# ESP32-C61 register map
Vendor: ESPRESSIF SYSTEMS (SHANGHAI) CO., LTD.; Series: ESP32 C-Series; File version: 1
CPU: RV32IMAC r0p0, little endian, no MPU, no FPU, 0 interrupt priority bits
Address unit: 32 bits
Registers are 32-bit, read-write, reset 0x0 unless marked. A register's access mark holds for its fields unless they carry their own. Offsets are from the block's base; [hi:lo] are bit positions; 'fields as' and 'values as' point back to an identical list.

## IO_MUX — Input/Output Multiplexer
Base 0x60090000
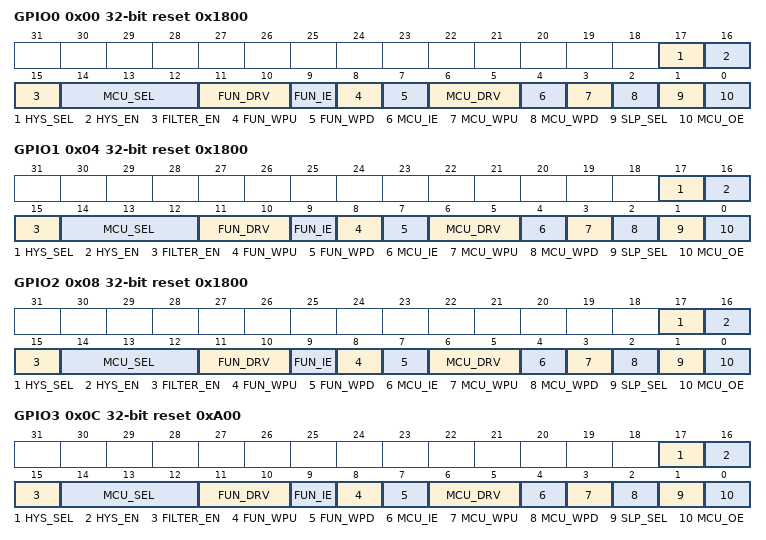
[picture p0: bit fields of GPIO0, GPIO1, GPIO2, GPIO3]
0x00 GPIO0 reset 0x1800 — IO_MUX Configure Register for pad XTAL_32K_P
  [17] HYS_SEL — Select enabling signals of the pad from software and efuse hardware. 1: Select enabling siganl from slftware. 0: Select enabling signal from efuse hardware.
  [16] HYS_EN — Software enables hysteresis function for the pad. 1: Hysteresis enabled. 0: Hysteresis disabled.
  [15] FILTER_EN — Enable filter for pin input signals. 1: Filter enabled. 0: Filter disabled.
  [14:12] MCU_SEL — Select IO MUX function for this signal. 0: Select Function 1. 1: Select Function 2. etc.
  [11:10] FUN_DRV — Select the drive strength of the pad.
  [9] FUN_IE — Input enable of the pad. 1: input enabled. 0: input disabled.
  [8] FUN_WPU — Pull-up enable of the pad. 1: internal pull-up enabled. 0: internal pull-up disabled.
  [7] FUN_WPD — Pull-down enable of the pad. 1: internal pull-down enabled. 0: internal pull-down disabled.
  [6:5] MCU_DRV — Select the drive strength of the pad during sleep mode.
  [4] MCU_IE — Input enable of the pad during sleep mode. 1: input enabled. 0: input disabled.
  [3] MCU_WPU — Pull-up enable of the pad during sleep mode. 1: internal pull-up enabled. 0: internal pull-up disabled.
  [2] MCU_WPD — Pull-down enable of the pad in sleep mode. 1: internal pull-down enabled. 0: internal pull-down disabled.
  [1] SLP_SEL — Sleep mode selection of this pad. Set to 1 to put the pad in pad mode.
  [0] MCU_OE — Output enable of the pad in sleep mode. 1: output enabled. 0: output disabled.
0x04 GPIO1 reset 0x1800 — IO_MUX Configure Register for pad XTAL_32K_N
  fields as GPIO0
0x08 GPIO2 reset 0x1800 — IO_MUX Configure Register for pad GPIO2
  fields as GPIO0
0x0C GPIO3 reset 0xA00 — IO_MUX Configure Register for pad MTMS
  fields as GPIO0
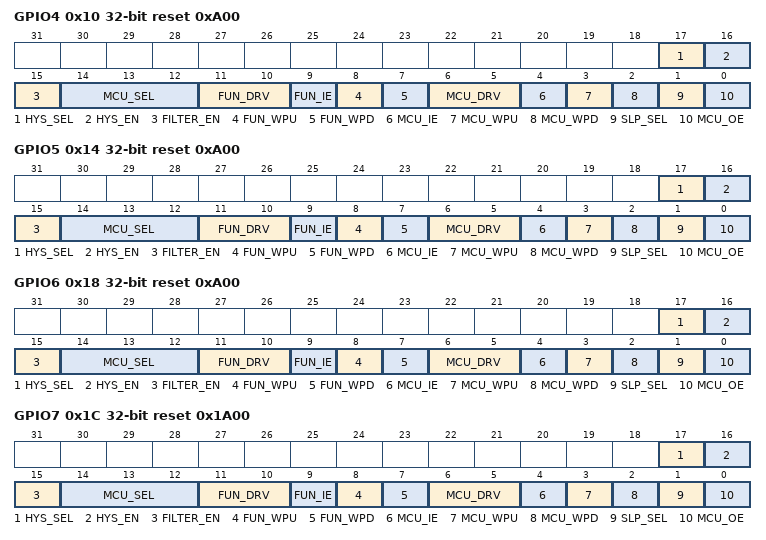
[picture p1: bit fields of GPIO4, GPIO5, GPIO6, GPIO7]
0x10 GPIO4 reset 0xA00 — IO_MUX Configure Register for pad MTDI
  fields as GPIO0
0x14 GPIO5 reset 0xA00 — IO_MUX Configure Register for pad MTCK
  fields as GPIO0
0x18 GPIO6 reset 0xA00 — IO_MUX Configure Register for pad MTDO
  fields as GPIO0
0x1C GPIO7 reset 0x1A00 — IO_MUX Configure Register for pad GPIO7
  fields as GPIO0
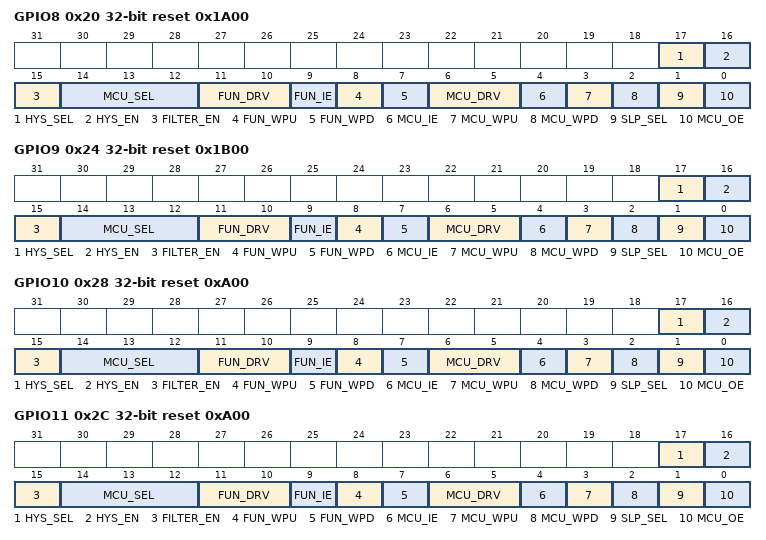
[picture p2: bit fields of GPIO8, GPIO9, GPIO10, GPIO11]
0x20 GPIO8 reset 0x1A00 — IO_MUX Configure Register for pad GPIO8
  fields as GPIO0
0x24 GPIO9 reset 0x1B00 — IO_MUX Configure Register for pad GPIO9
  fields as GPIO0
0x28 GPIO10 reset 0xA00 — IO_MUX Configure Register for pad U0RXD
  fields as GPIO0
0x2C GPIO11 reset 0xA00 — IO_MUX Configure Register for pad U0TXD
  fields as GPIO0
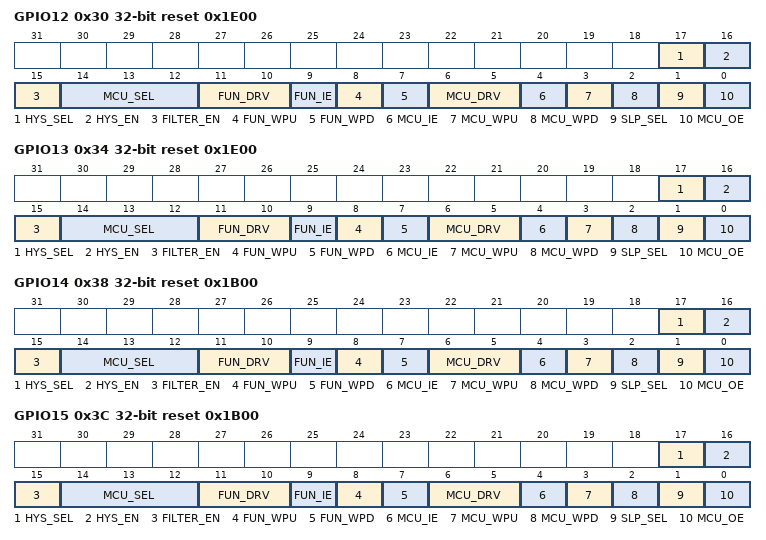
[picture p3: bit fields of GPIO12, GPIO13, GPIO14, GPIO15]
0x30 GPIO12 reset 0x1E00 — IO_MUX Configure Register for pad GPIO12
  fields as GPIO0
0x34 GPIO13 reset 0x1E00 — IO_MUX Configure Register for pad GPIO13
  fields as GPIO0
0x38 GPIO14 reset 0x1B00 — IO_MUX Configure Register for pad SPICS1
  fields as GPIO0
0x3C GPIO15 reset 0x1B00 — IO_MUX Configure Register for pad SPICS0
  fields as GPIO0
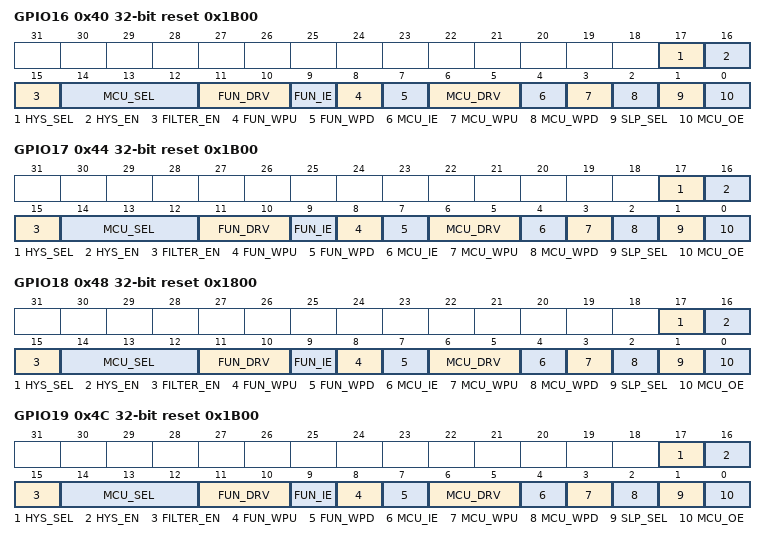
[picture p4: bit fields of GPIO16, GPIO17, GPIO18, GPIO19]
0x40 GPIO16 reset 0x1B00 — IO_MUX Configure Register for pad SPIQ
  fields as GPIO0
0x44 GPIO17 reset 0x1B00 — IO_MUX Configure Register for pad SPIWP
  fields as GPIO0
0x48 GPIO18 reset 0x1800 — IO_MUX Configure Register for pad VDD_SPI
  fields as GPIO0
0x4C GPIO19 reset 0x1B00 — IO_MUX Configure Register for pad SPIHD
  fields as GPIO0
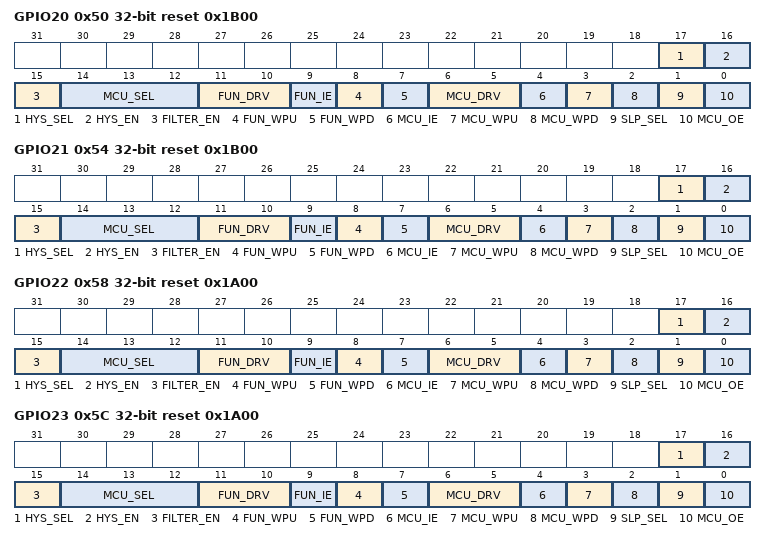
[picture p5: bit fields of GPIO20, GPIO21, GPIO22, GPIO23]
0x50 GPIO20 reset 0x1B00 — IO_MUX Configure Register for pad SPICLK
  fields as GPIO0
0x54 GPIO21 reset 0x1B00 — IO_MUX Configure Register for pad SPID
  fields as GPIO0
0x58 GPIO22 reset 0x1A00 — IO_MUX Configure Register for pad SDIO_DATA2
  fields as GPIO0
0x5C GPIO23 reset 0x1A00 — IO_MUX Configure Register for pad SDIO_DATA3
  fields as GPIO0
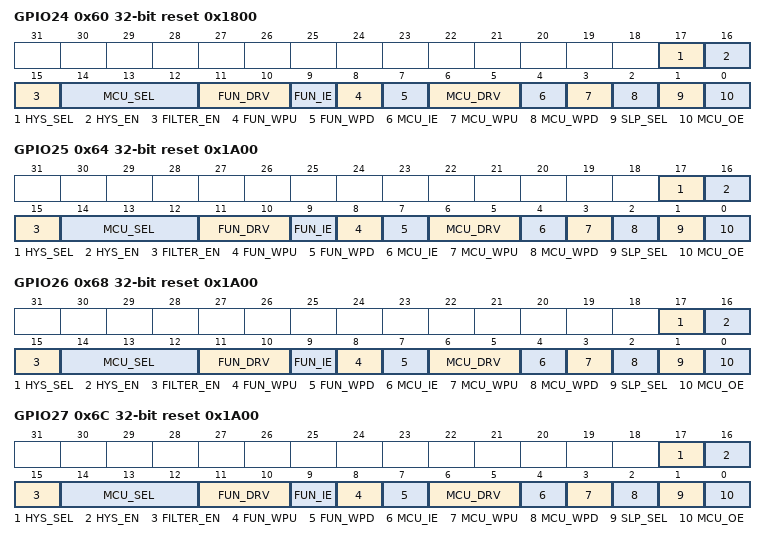
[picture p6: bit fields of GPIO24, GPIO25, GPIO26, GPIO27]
0x60 GPIO24 reset 0x1800 — IO_MUX Configure Register for pad GPIO24
  fields as GPIO0
0x64 GPIO25 reset 0x1A00 — IO_MUX Configure Register for pad SDIO_CMD
  fields as GPIO0
0x68 GPIO26 reset 0x1A00 — IO_MUX Configure Register for pad SDIO_CLK
  fields as GPIO0
0x6C GPIO27 reset 0x1A00 — IO_MUX Configure Register for pad SDIO_DATA0
  fields as GPIO0
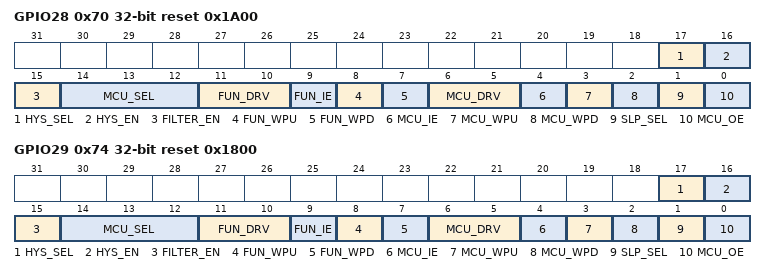
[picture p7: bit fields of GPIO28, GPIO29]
0x70 GPIO28 reset 0x1A00 — IO_MUX Configure Register for pad SDIO_DATA1
  fields as GPIO0
0x74 GPIO29 reset 0x1800 — IO_MUX Configure Register for pad GPIO29
  fields as GPIO0
0x1FC DATE reset 0x2412260 — IO_MUX Version Control Register
  [27:0] REG_DATE — Version control register
